# MSP430FR6972 register map
Registers are 16-bit, read-write, reset 0x0 unless marked. A register's access mark holds for its fields unless they carry their own. Offsets are from the block's base; [hi:lo] are bit positions; {n}, {i} and the like mark numbered series.

## MPU
Base 0x000005A0
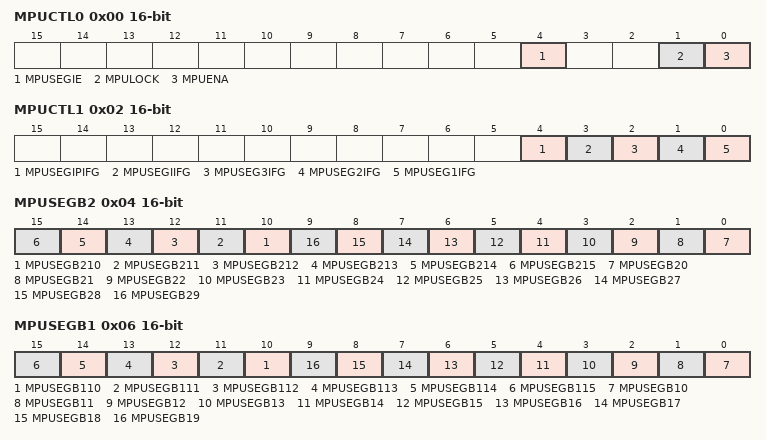
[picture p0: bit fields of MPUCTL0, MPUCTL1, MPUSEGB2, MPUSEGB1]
0x00 MPUCTL0 — MPU Control Register 0
  [4] MPUSEGIE — MPU Enable NMI on Segment violation
  [1] MPULOCK
  [0] MPUENA — MPU Enable
0x02 MPUCTL1 — MPU Control Register 1
  [4] MPUSEGIPIFG — MPU IP Memory Segment violation interupt flag
  [3] MPUSEGIIFG — MPU Info Memory Segment violation interupt flag
  [2] MPUSEG3IFG — MPU Main Memory Segment 3 violation interupt flag
  [1] MPUSEG2IFG — MPU Main Memory Segment 2 violation interupt flag
  [0] MPUSEG1IFG — MPU Main Memory Segment 1 violation interupt flag
0x04 MPUSEGB2 — MPU Segmentation Border 2 Register
  [n-200] MPUSEGB{n} (n=210..215) — MPU Segment Border 2 Bit: {n-200}
  [n-20] MPUSEGB{n} (n=20..29) — MPU Segment Border 2 Bit: {n-20}
0x06 MPUSEGB1 — MPU Segmentation Border 1 Register
  [n-100] MPUSEGB{n} (n=110..115) — MPU Segment Border 1 Bit: {n-100}
  [n-10] MPUSEGB{n} (n=10..19) — MPU Segment Border 1 Bit: {n-10}
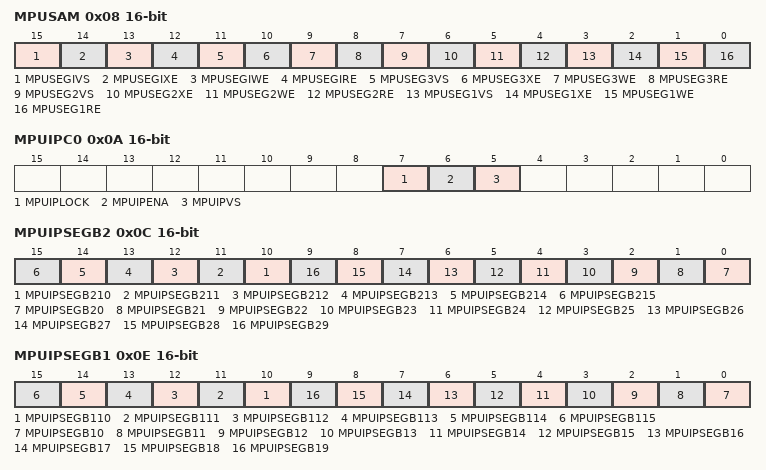
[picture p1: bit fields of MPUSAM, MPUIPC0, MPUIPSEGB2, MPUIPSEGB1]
0x08 MPUSAM — MPU Access Management Register
  [15] MPUSEGIVS — MPU Info memory Segment Violation select
  [14] MPUSEGIXE — MPU Info memory Segment Execute enable
  [13] MPUSEGIWE — MPU Info memory Segment Write enable
  [12] MPUSEGIRE — MPU Info memory Segment Read enable
  [11] MPUSEG3VS — MPU Main memory Segment 3 Violation select
  [10] MPUSEG3XE — MPU Main memory Segment 3 Execute enable
  [9] MPUSEG3WE — MPU Main memory Segment 3 Write enable
  [8] MPUSEG3RE — MPU Main memory Segment 3 Read enable
  [7] MPUSEG2VS — MPU Main memory Segment 2 Violation select
  [6] MPUSEG2XE — MPU Main memory Segment 2 Execute enable
  [5] MPUSEG2WE — MPU Main memory Segment 2 Write enable
  [4] MPUSEG2RE — MPU Main memory Segment 2 Read enable
  [3] MPUSEG1VS — MPU Main memory Segment 1 Violation select
  [2] MPUSEG1XE — MPU Main memory Segment 1 Execute enable
  [1] MPUSEG1WE — MPU Main memory Segment 1 Write enable
  [0] MPUSEG1RE — MPU Main memory Segment 1 Read enable
0x0A MPUIPC0 — MPU IP Control 0 Register
  [7] MPUIPLOCK — MPU IP Protection Lock
  [6] MPUIPENA — MPU MPU IP Protection Enable
  [5] MPUIPVS — MPU MPU IP protection segment Violation Select
0x0C MPUIPSEGB2 — MPU IP Segment Border 2 Register
  [n-200] MPUIPSEGB{n} (n=210..215) — MPU IP Segment Border 2 Bit: {n-200}
  [n-20] MPUIPSEGB{n} (n=20..29) — MPU IP Segment Border 2 Bit: {n-20}
0x0E MPUIPSEGB1 — MPU IP Segment Border 1 Register
  [n-100] MPUIPSEGB{n} (n=110..115) — MPU IP Segment Border 1 Bit: {n-100}
  [n-10] MPUIPSEGB{n} (n=10..19) — MPU IP Segment Border 1 Bit: {n-10}

## CRC32
Base 0x00000980
0x00 CRC32DIW0 — CRC32 Data In
0x02 CRC32DIW1 — CRC32 Data In
0x04 CRC32DIRBW1 — CRC32 Data In Reversed Bit
0x06 CRC32DIRBW0 — CRC32 Data In Reversed Bit
0x08 CRC32INIRESW0 — CRC32 Initialization and Result
0x0A CRC32INIRESW1 — CRC32 Initialization and Result
0x0C CRC32RESRW1 — CRC32 Result Reverse
0x0E CRC32RESRW0 — CRC32 Result Reverse
0x10 CRC16DIW0 — CRC16 Data Input
0x12 CRC16DIW1 — CRC16 Data Input
0x14 CRC16DIRBW1 — CRC16 Data In Reverse
0x16 CRC16DIRBW0 — CRC16 Data In Reverse
0x18 CRC16INIRESW0 — CRC16 Init and Result
0x1C CRC16RESRW1 — CRC16 Result Reverse
0x1E CRC16RESRW0 — CRC16 Result Reverse

## AES_ACCELERATOR
Base 0x000009C0
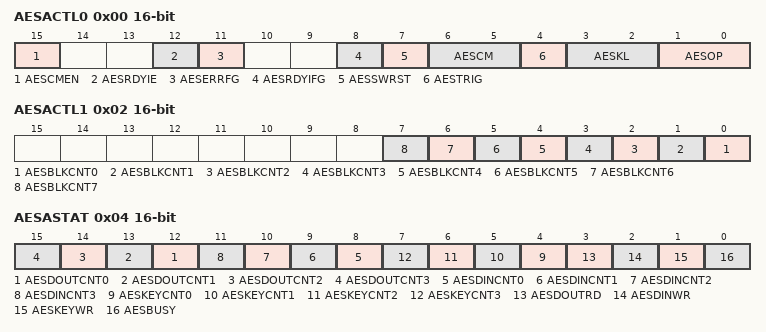
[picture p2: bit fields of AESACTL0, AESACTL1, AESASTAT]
0x00 AESACTL0 — AES accelerator control register 0
  [15] AESCMEN — AES DMA cipher mode enable
  [12] AESRDYIE — AES ready interrupt enable
  [11] AESERRFG — AES Error Flag
  [8] AESRDYIFG — AES ready interrupt flag
  [7] AESSWRST — AES Software Reset
  [6:5] AESCM — AES Cipher mode select Bit: 0
    0=AES Cipher mode select: ECB; 1=AES Cipher mode select: CBC; 2=AES Cipher mode select: OFB; 3=AES Cipher mode select: CFB
  [4] AESTRIG — AES Trigger Select
  [3:2] AESKL — AES Key length Bit: 0
    0=AES Key length: AES128; 1=AES Key length: AES192; 2=AES Key length: AES256
  [1:0] AESOP — AES Operation Bit: 0
    0=AES Operation: Encrypt; 1=AES Operation: Decrypt (same Key); 2=AES Operation: Generate first round Key; 3=AES Operation: Decrypt (first round Key)
0x02 AESACTL1 — AES accelerator control register 1
  [n] AESBLKCNT{n} (n=0..7) — AES Cipher Block Counter Bit: {n}
0x04 AESASTAT — AES accelerator status register
  [n+12] AESDOUTCNT{n} (n=0..3) — AES Bytes read via AESADOUT Bit: {n}
  [n+8] AESDINCNT{n} (n=0..3) — AES Bytes written via AESADIN Bit: {n}
  [n+4] AESKEYCNT{n} (n=0..3) — AES Bytes written via AESAKEY Bit: {n}
  [3] AESDOUTRD — AES All 16 bytes read from AESADOUT
  [2] AESDINWR — AES All 16 bytes written to AESADIN
  [1] AESKEYWR — AES All 16 bytes written to AESAKEY
  [0] AESBUSY
0x06 AESAKEY — AES accelerator key register
0x08 AESADIN — AES accelerator data in register
0x0A AESADOUT — AES accelerator data out register
0x0C AESAXDIN — AES accelerator XORed data in register
0x0E AESAXIN — AES accelerator XORed data in register (no trigger)
